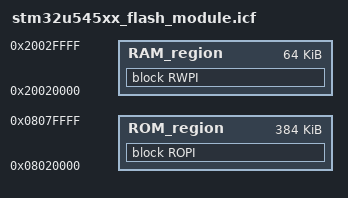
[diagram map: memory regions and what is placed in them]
/*###ICF### Section handled by ICF editor, don't touch! ****/
/*-Editor annotation file-*/
/* IcfEditorFile="$TOOLKIT_DIR$\config\ide\IcfEditor\cortex_v1_0.xml" */
/*-Specials-*/
define symbol __ICFEDIT_intvec_start__ = 0x08000000;
/*-Memory Regions-*/
define symbol __ICFEDIT_region_ROM_start__ = 0x08020000;
define symbol __ICFEDIT_region_ROM_end__   = 0x0807FFFF;
define symbol __ICFEDIT_region_RAM_start__ = 0x20020000;
define symbol __ICFEDIT_region_RAM_end__   = 0x2002FFFF;

/*-Sizes-*/
define symbol __ICFEDIT_size_cstack__ = 0x800;
define symbol __ICFEDIT_size_heap__   = 0x400;
/**** End of ICF editor section. ###ICF###*/


define memory mem with size = 4G;
define region ROM_region      = mem:[from __ICFEDIT_region_ROM_start__   to __ICFEDIT_region_ROM_end__];
define region RAM_region      = mem:[from __ICFEDIT_region_RAM_start__   to __ICFEDIT_region_RAM_end__];

define block HEAP      with alignment = 8, size = __ICFEDIT_size_heap__     { };

initialize by copy { readwrite };
do not initialize  { section .noinit };

define movable block ROPI with alignment = 4, fixed order
{
  ro object txm_module_preamble.o,
  ro,
  ro data
};

define movable block RWPI with alignment = 8, fixed order, static base
{
  rw,
  block HEAP
};

place in ROM_region   { block ROPI };
place in RAM_region   { block RWPI };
